# DISPC register map
Vendor: Texas Instruments
Peripheral module from a debugger description file (folder TDA2Px).
Registers are 32-bit, access per field, reset 0x0 unless marked. A register's access mark holds for its fields unless they carry their own. Offsets are as the file gives them; lines under a group give offsets from that group; [hi:lo] are bit positions; {n}, {i} and the like mark numbered series; 'fields as' and 'values as' point back to an identical list; <NAME> marks a mode.

## DISPC (part 1 of 6)
0x00 DISPC_REVISION ro reset not defined — IP Revision
  [31:0] REVISION — IP revision
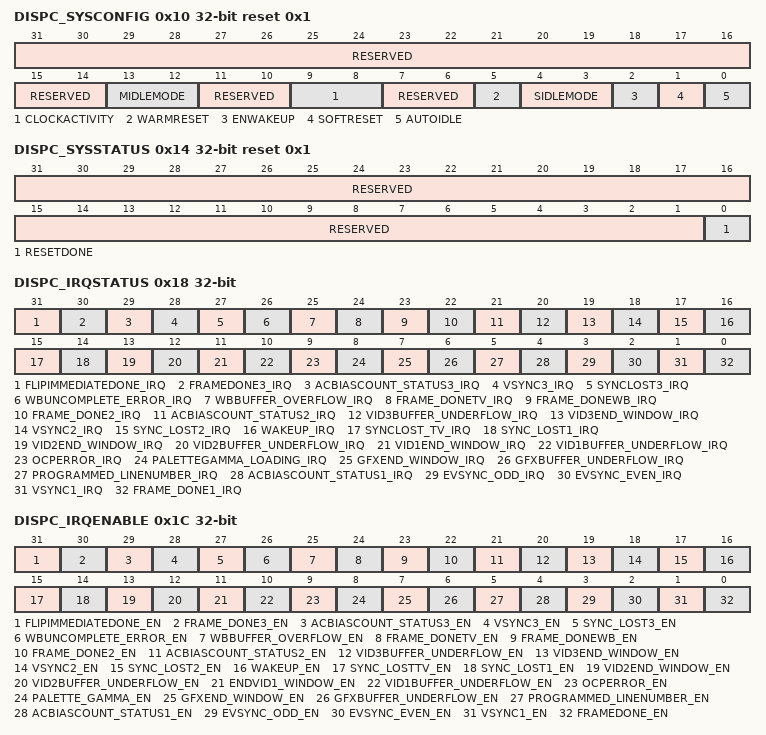
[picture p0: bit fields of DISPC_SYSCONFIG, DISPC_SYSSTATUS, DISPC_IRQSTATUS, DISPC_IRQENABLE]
0x10 DISPC_SYSCONFIG reset 0x1 — This register allows to control various parameters of the OCP interface.
  [31:14] RESERVED ro — Write 0s for future compatibility. Reads returns 0.
  [13:12] MIDLEMODE rw — Master interface power management, standby/wait control
    0=fStandBy (Force-standby. MStandby is only asserted when the module is disabled. MStandby is only asserted when the module is disabled.); 1=nStandBy (No-Standby: MStandby is never asserted.); 2=Sstandby (Smart-Standby. MStandby is asserted based on the internal activity of the module.)
  [11:10] RESERVED ro — Write 0s for future compatibility. Reads returns 0
  [9:8] CLOCKACTIVITY rw — Clocks activity during wake up mode period
    0=OCPFuncOff (OCP and functional clocks can be switched off.); 1=FuncOff (Functional clocks can be switched off and OCP clocks are maintained during wake up period.); 2=OCPOff (OCP clocks can be switched off and Functional clocks are maintained during wake up period.); 3=OCPFuncOn (OCP and functional clocks are maintained during wake-up period.)
  [7:6] RESERVED ro — Write 0s for future compatibility. Reads returns 0
  [5] WARMRESET rw — Warm reset. Set this bit to 1 triggers a module warm reset. The bit is automatically reset by the hardware. During reads, it always returns 0. The warm reset keep the configuration registers unchanged.
    0=Normal mode; 1=warmreset (The warm reset is set.)
  [4:3] SIDLEMODE rw — Slave interface power management, Idle req/ack control
    0=fIdle (Force-idle. An idle request is acknowledged unconditionally.); 1=nIdle (No-idle. An idle request is never acknowledged.); 2=sIdle (Smart-idle. Acknowledgment to an idle request is given based on the internal activity of the module.)
  [2] ENWAKEUP rw — WakeUp feature control
    0=WakeUpDis (Wakeup is disabled.); 1=WakeUpEnb (Wakeup is enabled.)
  [1] SOFTRESET rw — Software reset. Set this bit to 1 to trigger a module reset. The bit is automatically reset by the hardware. During reads, it always returns 0.
    0=nMode (Normal mode); 1=Rst (The module is reset.)
  [0] AUTOIDLE rw — Internal interface clock gating strategy
    0=ClkFree (Interface clock is free-running.); 1=ClkGated (Automatic interface L3_MAIN gating strategy is applied, based on the OCP interface activity. Automatic functional clock gating is also applied to the functional clock based on the module activity (for instance DISPC_<pipe>_ATTRIBUTES.ENABLE).)
0x14 DISPC_SYSSTATUS ro reset 0x1 — This register provides status information about the module, excluding the interrupt status information.
  [31:1] RESERVED — Write 0s for future compatibility. Reads return 0.
  [0] RESETDONE — Internal reset monitoring
    0=rstongoing (Internal module reset is on-going.); 1=rstcomp (Reset completed)
0x18 DISPC_IRQSTATUS access not given — This register regroups all the status of the module internal events that generate an interrupt. Write 1 to a given bit resets this bit
  [31] FLIPIMMEDIATEDONE_IRQ — Flip Immediate Done. The DMA engine has acknowledged the immediate BA change, and software can write the new BA0. (access RW W1toClr)
    0=False (READS: Event is false. WRITES: Status bit unchanged.); 1=True (READS: Event is true (pending). WRITES: Status bit is reset.)
  [30] FRAMEDONE3_IRQ — Frame done for the third LCD. The third LCD output has been disabled by user. All the data have been sent. (access RW W1toClr)
    values as FLIPIMMEDIATEDONE_IRQ
  [29] ACBIASCOUNT_STATUS3_IRQ — AC bias count status for the third LCD (access RW W1toClr)
    values as FLIPIMMEDIATEDONE_IRQ
  [28] VSYNC3_IRQ — Vertical synchronization for the third LCD (access RW W1toClr)
    values as FLIPIMMEDIATEDONE_IRQ
  [27] SYNCLOST3_IRQ — Synchronization lost on the third LCD output. The required data are not output at the correct time due to too short blanking periods or stall of at least one pipelines associated with the third LCD output. (access RW W1toClr)
    values as FLIPIMMEDIATEDONE_IRQ
  [26] WBUNCOMPLETE_ERROR_IRQ — Write-back DMA buffer is flushed before it is completely drained.In WB capture mode, if the new frame starts before the WB DMA buffers are fully drained (onto external memory), then the contents of the WB DMA buffers are lost (implying last few pixels/lines are corrupted in the captured frame in memory). This interrupt is an indication of that case and will trigger every frame . (access RW W1toClr)
    0=READS:_WRITES:_0 (READS: Event is false. WRITES: Status bit unchanged); 1=READS:_WRITES:_1 (READS: Event is true (Pending) WRITES: Status bit is reset)
  [25] WBBUFFER_OVERFLOW_IRQ — Write-back DMA buffer overflow. The DMA buffer is full. (access RW W1toClr)
    0=READS:_WRITES:_0 (READS: Event is false. WRITES: Status bit unchanged.); 1=READS:_WRITES:_1 (READS: Event is true (pending). WRITES: Status bit is reset.)
  [24] FRAME_DONETV_IRQ — Frame done for the TV. The TV output has been disabled by user. All the data have been sent. (access RW W1toClr)
    values as FLIPIMMEDIATEDONE_IRQ
  [23] FRAME_DONEWB_IRQ — Frame done for the write-back channel. The write-back channel has output the frame. All the data of the frame have been sent to the memory. There is no pending data inside the DMA engine for the write-back channel to be transferred to memory. It is available only when the write-back pipeline transfers back to memory the output of one of the pipelines. In case of overlay capture, the interrupt is not generated and the user shall use the FrameDone for the corresponding captured output. (access RW W1toClr)
    values as FLIPIMMEDIATEDONE_IRQ
  [22] FRAME_DONE2_IRQ — Frame done for the secondary LCD. The secondary LCD output has been disabled by user. All the data have been sent. (access RW W1toClr)
    values as FLIPIMMEDIATEDONE_IRQ
  [21] ACBIASCOUNT_STATUS2_IRQ — AC bias count status for the secondary LCD (access RW W1toClr)
    values as FLIPIMMEDIATEDONE_IRQ
  [20] VID3BUFFER_UNDERFLOW_IRQ — Video 3 DMA buffer underflow. The DMA buffer is not necessarily empty but required data are not present in the DMA buffer (due to out of order responses) (access RW W1toClr)
    values as FLIPIMMEDIATEDONE_IRQ
  [19] VID3END_WINDOW_IRQ — The end of the video 3 window has been reached. It is detected by the overlay manager when the full video 3 has been displayed. (access RW W1toClr)
    values as FLIPIMMEDIATEDONE_IRQ
  [18] VSYNC2_IRQ — Vertical synchronization for the secondary LCD (access RW W1toClr)
    values as FLIPIMMEDIATEDONE_IRQ
  [17] SYNC_LOST2_IRQ — Synchronization lost on the secondary LCD output. The required data are not output at the correct time due to too short blanking periods or stall of at least one pipelines associated with the secondary LCD output. (access RW W1toClr)
    values as FLIPIMMEDIATEDONE_IRQ
  [16] WAKEUP_IRQ — Wakeup (access RW W1toClr)
    values as FLIPIMMEDIATEDONE_IRQ
  [15] SYNCLOST_TV_IRQ — Synchronization lost on the TV output. The required data are not output at the correct time due to too short blanking periods or stall of at least one pipelines associated with the TV output. (access RW W1toClr)
    values as FLIPIMMEDIATEDONE_IRQ
  [14] SYNC_LOST1_IRQ — Synchronizationl ost on the primary LCD output. The required data are not output at the correct time due to too short blanking periods or stall of at least one pipelines associated with the primary LCD output. (access RW W1toClr)
    values as FLIPIMMEDIATEDONE_IRQ
  [13] VID2END_WINDOW_IRQ — The end of the video 2 Window has been reached. It is detected by the overlay manager when the full video 2 has been displayed. (access RW W1toClr)
    values as FLIPIMMEDIATEDONE_IRQ
  [12] VID2BUFFER_UNDERFLOW_IRQ — Video 2 DMA buffer underflow. The DMA buffer is not necessarily empty but required data are not present in the DMA buffer (due to out of order responses) (access RW W1toClr)
    values as FLIPIMMEDIATEDONE_IRQ
  [11] VID1END_WINDOW_IRQ — The end of the video 1 Window has been reached. It is detected by the overlay manager when the full video 1 has been displayed. (access RW W1toClr)
    values as FLIPIMMEDIATEDONE_IRQ
  [10] VID1BUFFER_UNDERFLOW_IRQ — Video 1 DMA buffer underflow. The DMA buffer is not necessarily empty but required data are not present in the DMA buffer (due to out of order responses) (access RW W1toClr)
    values as FLIPIMMEDIATEDONE_IRQ
  [9] OCPERROR_IRQ — OCP error. L3_MAIN Interconnect has sent SResp=ERR. (access RW W1toClr)
    values as FLIPIMMEDIATEDONE_IRQ
  [8] PALETTEGAMMA_LOADING_IRQ — Palette Gamma loading status. The palette used as Color Look Up Table (CLUT) for the graphics BITMAP formats (1-, 2-, 4-, or 4-bpp) or as gamma table for the overlay output for the primary LCD output has been loaded successfully.NOTE: CLUT and BITMAP formats are not supported in this family of devices. . (access RW W1toClr)
    values as FLIPIMMEDIATEDONE_IRQ
  [7] GFXEND_WINDOW_IRQ — The end of the graphics wndow has been reached. It is detected by the overlay manager when the full graphics has been displayed. (access RW W1toClr)
    values as FLIPIMMEDIATEDONE_IRQ
  [6] GFXBUFFER_UNDERFLOW_IRQ — Graphics DMA buffer underflow. The DMA buffer is not necessarily empty but required data are not present in the DMA buffer (due to out of order responses) (access RW W1toClr)
    values as FLIPIMMEDIATEDONE_IRQ
  [5] PROGRAMMED_LINENUMBER_IRQ — Programmed line number. It indicates that the scan of the primary LCD has reached the programmed user line number. (access RW W1toClr)
    values as FLIPIMMEDIATEDONE_IRQ
  [4] ACBIASCOUNT_STATUS1_IRQ — AC bias count status for the primary LCD (access RW W1toClr)
    values as FLIPIMMEDIATEDONE_IRQ
  [3] EVSYNC_ODD_IRQ — VSYNC for odd field from the TV encoder (HDMI) (access RW W1toClr)
    values as FLIPIMMEDIATEDONE_IRQ
  [2] EVSYNC_EVEN_IRQ — VSYNC for even field from the TV encoder (HDMI) (access RW W1toClr)
    values as FLIPIMMEDIATEDONE_IRQ
  [1] VSYNC1_IRQ — Vertical synchronization for the primary LCD. (access RW W1toClr)
    values as FLIPIMMEDIATEDONE_IRQ
  [0] FRAME_DONE1_IRQ — Frame done for the primary LCD. The primary LCD output has been disabled by user. All the data have been sent. (access RW W1toClr)
    values as FLIPIMMEDIATEDONE_IRQ
0x1C DISPC_IRQENABLE rw — This register allows to mask/unmask the module internal sources of interrupt, on an event-by-event basis
  [31] FLIPIMMEDIATEDONE_EN — Flip Immediate Done. The DMA engine has acknowledged the immediate BA change, and software can write the new BA0.
    0=masked (FrameDone for the primary LCD output is masked); 1=genint (FrameDone for the primary LCD output generates an interrupt when it occurs)
  [30] FRAME_DONE3_EN — Frame done for the third LCD. The third LCD output has been disabled by user. All the data have been sent.
    0=masked (Frame Done for the secondary LCD is masked.); 1=genint (Frame Done for the secondary LCD generates an interrupt when it occurs.)
  [29] ACBIASCOUNT_STATUS3_EN — AC Bias count status for the third LCD
    0=masked (ACBiasCountStatus for the secondary LCD output is masked); 1=genint (ACBiasCountStatus for the secondary LCD output generates an interrupt when it occurs)
  [28] VSYNC3_EN — Vertical synchronization for the third LCD
    0=masked (VSYNC for the secondary LCD output is masked.); 1=genint (VSYNC for the secondary LCD output generates an interrupt when it occurs.)
  [27] SYNC_LOST3_EN — Synchronization lost on the third LCD output. The required data are not output at the correct time due to too short blanking periods or stall of at least one pipelines associated with the third LCD output.
    0=masked (Synchronization Lost on the secondary LCD output is masked.); 1=genint (Synchronization Lost on the secondary LCD output generates an interrupt when it occurs.)
  [26] WBUNCOMPLETE_ERROR_EN — The write back buffer has been flushed before been fully drained. Enable.
    0=masked (Interrupt is masked.); 1=genint (Interrupt is enabled.)
  [25] WBBUFFER_OVERFLOW_EN — Write-back DMA buffer overflow. The DMA buffer is full.
    0=masked (WBBufferOverflow is masked.); 1=genint (WBBufferOverflow generates an interrupt when it occurs.)
  [24] FRAME_DONETV_EN — Frame done for the TV. The TV output has been disabled by user. All the data have been sent.
    0=masked (Frame Done for the TV output is masked.); 1=genint (Frame Done for the TV output generates an interrupt when it occurs.)
  [23] FRAME_DONEWB_EN — Frame done for the write-back channel. The write-back channel has output the frame. All the data have been sent for the frame have been sent to the memory. There is no pending data inside the DMA engine for the write-back channel to be transferred to memory.
    0=masked (Frame done for the write-back is masked.); 1=genint (Frame done for the write-back generates an interrupt when it occurs.)
  [22] FRAME_DONE2_EN — Frame done for the secondary LCD. The secondary LCD output has been disabled by user. All the data have been sent.
    0=masked (Frame done for the secondary LCD is masked.); 1=genint (Frame done for the secondary LCD generates an interrupt when it occurs.)
  [21] ACBIASCOUNT_STATUS2_EN — AC Bias count status for the secondary LCD
    0=masked (ACBiasCountStatus for the secondary LCD output is masked.); 1=genint (ACBiasCountStatus for the secondary LCD output generates an interrupt when it occurs.)
  [20] VID3BUFFER_UNDERFLOW_EN — Video 3 DMA Buffer Underflow. The DMA buffer is not necessary empty but required data are not present in the DMA buffer (due to out of order responses)
    0=masked (Vid3BufferUnderflow is masked.); 1=genint (Vid3BufferUnderflow generates an interrupt when it occurs.)
  [19] VID3END_WINDOW_EN — The end of the video 3 window has been reached. It is detected by the overlay manager when the full video 3 has been displayed.
    0=masked (Vid3EndWindow is masked.); 1=genint (Vid3EndWindow generates an interrupt when it occurs.)
  [18] VSYNC2_EN — Vertical synchronization for the secondary LCD
    values as VSYNC3_EN
  [17] SYNC_LOST2_EN — Synchronization lost on the secondary LCD output. The required data are not output at the correct time due to too short blanking periods or stall of at least one pipelines associated with the secondary LCD output.
    values as SYNC_LOST3_EN
  [16] WAKEUP_EN — Wake up mask
    0=masked (WakeUp is masked.); 1=genint (WakeUp generates an interrupt when it occurs.)
  [15] SYNC_LOSTTV_EN — Synchronization lost on the TV output. The required data are not output at the correct time due to too short blanking periods or stall of at least one pipelines associated with the TV output.
    0=masked (Synchronization Lost on the TV output is masked.); 1=genint (Synchronization Lost on the TV output generates an interrupt when it occurs.)
  [14] SYNC_LOST1_EN — Synchronization lost for the primary LCD
    0=masked (SyncLost for the primary LCD output is masked.); 1=genint (SyncLost for the primary LCD output generates an interrupt when it occurs.)
  [13] VID2END_WINDOW_EN — The end of the video 2 Window has been reached. It is detected by the overlay manager when the full video 2 has been displayed.
    0=masked (Vid2EndWindow is masked.); 1=genint (Vid2EndWindow generates an interrupt when it occurs.)
  [12] VID2BUFFER_UNDERFLOW_EN — Video 2 DMA buffer underflow. The DMA buffer is not necessary empty but required data are not present in the DMA buffer (due to out of order responses)
    0=masked (Vid2BufferUnderflow is masked.); 1=genint (Vid2BufferUnderflow generates an interrupt when it occurs.)
  [11] ENDVID1_WINDOW_EN — The end of the video 1 window has been reached. It is detected by the overlay manager when the full video 1 has been displayed.
    0=masked (EndVid1Window is masked.); 1=genint (EndVid1Window generates an interrupt when it occurs.)
  [10] VID1BUFFER_UNDERFLOW_EN — Video 1 DMA buffer underflow. The DMA buffer is not necessary empty but required data are not present in the DMA buffer (due to out of order responses)
    0=masked (Vid1bufferunderflow is masked.); 1=genint (Vid1bufferunderflow generates an interrupt when it occurs.)
  [9] OCPERROR_EN — OCP Error. L3_MAIN Interconnect has sent SResp=ERR.
    0=masked (OCPError is masked.); 1=genint (OCPError generates an interrupt when it occurs.)
  [8] PALETTE_GAMMA_EN — Palette gamma loading mask. The palette used as Color Look Up Table (CLUT) for the graphics BITMAP formats (1-, 2-, 4-, or 4-bpp) or as gamma table for the overlay output for the primary LCD output has been loaded successfully.NOTE: CLUT and BITMAP formats are not supported in this family of devices. .
    0=masked (PaletteGamma is masked.); 1=genint (PaletteGamma generates an interrupt when it occurs.)
  [7] GFXEND_WINDOW_EN — The end of the graphics Window has been reached. It is detected by the overlay manager when the full graphics has been displayed.
    0=masked (GfxEndWindow is masked.); 1=genint (GfxEndWindow generates an interrupt when it occurs.)
  [6] GFXBUFFER_UNDERFLOW_EN — Graphics DMA Buffer Underflow. The DMA buffer is not necessarily empty but required data are not present in the DMA buffer (due to out of order responses)
    0=masked (GfxBufferUnderflow is masked.); 1=genint (GfxBufferUnderflow generates an interrupt when it occurs.)
  [5] PROGRAMMED_LINENUMBER_EN — Programmed Line Number. It indicates that the scan of the primary LCD has reached the programmed user line number.
    0=masked (ProgrammedLineNumber is masked.); 1=genint (ProgrammedLineNumber generates an interrupt when it occurs.)
  [4] ACBIASCOUNT_STATUS1_EN — AC Bias count status for the primary LCD
    0=masked (ACBiascountstatus for the primary LCD output is masked.); 1=genint (ACBiascountstatus for the primary LCD output generates an interrupt when it occurs.)
  [3] EVSYNC_ODD_EN — VSYNC for odd field from the TV encoder (HDMI)
    0=masked (EVSYNC_ODD for the TV output is masked.); 1=genint (EVSYNC_ODD for the TV output generates an interrupt when it occurs.)
  [2] EVSYNC_EVEN_EN — VSYNC for even field from the TV encoder (HDMI)
    0=masked (EVSYNC_EVEN for the TV output is masked.); 1=genint (EVSYNC_EVEN for the TV output generates an interrupt when it occurs.)
  [1] VSYNC1_EN — Vertical synchronization for the primary LCD.
    0=masked (VSYNC for the primary LCD output is masked.); 1=genint (VSYNC for the primary LCD output generates an interrupt when it occurs.)
  [0] FRAMEDONE_EN — Frame done for the primary LCD. The primary LCD output has been disabled by user. All the data have been sent.
    0=masked (Frame Done for the primary LCD output is masked.); 1=genint (FrameDone for the primary LCD output generates an interrupt when it occurs.)
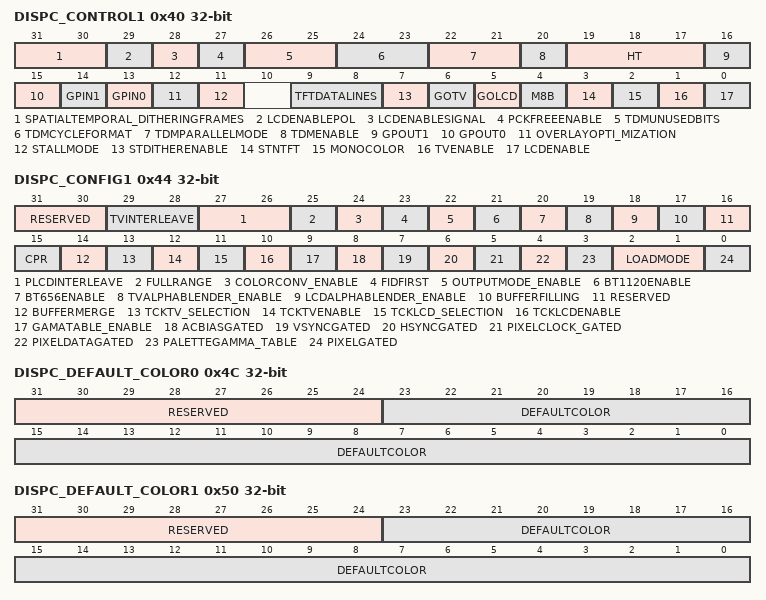
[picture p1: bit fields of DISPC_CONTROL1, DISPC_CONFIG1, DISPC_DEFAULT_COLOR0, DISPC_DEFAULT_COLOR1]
0x40 DISPC_CONTROL1 — The control register configures the Display Controller module for the primary LCD and TV outputs.
  [31:30] SPATIALTEMPORAL_DITHERINGFRAMES rw — Spatial/temporal dithering number of frames for the primary LCD output wr: VFP start period of primary LCD
    0=OneFrame (Spatial only); 1=TwoFrames (Spatial and temporal over 2 frames); 2=FourFrames (Spatial and temporal over 4 frames)
  [29] LCDENABLEPOL ro — Write 0s for future compatibility. Reads return 0.
  [28] LCDENABLESIGNAL ro — Write 0s for future compatibility. Reads return 0.
  [27] PCKFREEENABLE ro — Write 0s for future compatibility. Reads return 0.
  [26:25] TDMUNUSEDBITS rw — State of unused bits (TDM mode only) for the primary LCD output. wr: VFP start period of primary LCD
    0=Low level (0); 1=High level (1); 2=Unchanged from previous state
  [24:23] TDMCYCLEFORMAT rw — Cycle format (TDM mode only) for the primary LCD output WR: VFP start period of primary LCD
    0=1CycPerPix (1 cycle for 1 pixel); 1=2CycPerPix (2 cycles for 1 pixel); 2=3CycPerPix (3 cycles for 1 pixel); 3=3CycPer2Pix (3 cycles for 2 pixels)
  [22:21] TDMPARALLELMODE rw — Output interface width (TDM mode only) for the primary LCD output WR: VFP start period of primary LCD
    0=8bParaInt (8-bit parallel output interface selected); 1=9bParaInt (9-bit parallel output interface selected); 2=12bParaInt (12-bit parallel output interface selected); 3=16bParaInt (16-bit parallel output interface selected)
  [20] TDMENABLE rw — Enable the multiple cycle format for the primary LCD output. WR: VFP start period of primary LCD
    0=TDM disabled; 1=TDMEnb (TDM enabled)
  [19:17] HT rw — Hold time for TV output WR: EVSYNC Encoded value (from 1 to 8) to specify the number of external digital clock periods to hold the data (programmed value = value minus 1)
  [16] GPOUT1 rw — General purpose output signal l WR: immediate
    0=reset (The GPout1 is reset.); 1=set (The GPout1 is set.)
  [15] GPOUT0 rw — General Purpose Output Signal WR:immediate
    0=reset (The GPout0 is reset.); 1=set (The GPout0 is set.)
  [14] GPIN1 ro — General purpose input signal WR: immediately
    0=reset (The GPin1 has been reset.); 1=set (The GPin1 has been set.)
  [13] GPIN0 ro — General purpose input signal WR: immediately
    0=GPin0Rst (The GPin0 has been reset.); 1=GPin0Set (The GPin0 has been set.)
  [12] OVERLAYOPTI_MIZATION rw — Overlay optimization for the primary LCD output WR: VFP start period of the primary LCD
    0=GDBVWfM (All the data for all the enabled pipelines are fetched from memory regardless of the overlay/alpha blending configuration.); 1=GDBVWnfM (The data not used by the overlay manager because of overlap between layers with no alpha blending between them must not be fetched from memory in order to optimize the bandwidth.)
  [11] STALLMODE rw — STALL mode for the primary LCD output wr: VFP start period of primary LCD
    0=Normal_mode_selected; 1=STALL_VSYNC/HSYNC._LCD_LCD_1 (STALL mode selected. The Display Controller sends the data without considering the VSYNC/HSYNC. The LCD output is disabled at the end of the transfer of the frame. To generate a new frame, the software must re-enable the LCD output.)
  [9:8] TFTDATALINES rw — Number of lines of the primary LCD interface WR: VFP start period of primary LCD
    0=OaLSB12b (12-bit output aligned on the LSB of the pixel data interface); 1=OaLSB16b (16-bit output aligned on the LSB of the pixel data interface); 2=OaLSB18b (18-bit output aligned on the LSB of the pixel data interface); 3=OaLSB24b (24-bit output aligned on the LSB of the pixel data interface)
  [7] STDITHERENABLE rw — Spatial temporal dithering enable for the primary LCD output WR: VFP start period of primary LCD
    0=STDithDis (Spatial/temporal dithering logic disabled); 1=STDithEnb (Spatial/temporal dithering logic enabled)
  [6] GOTV rw — GO command for the TV output. It is used to synchronized the pipelines (graphics and/or video ones) associated with the TV output. WR: immediate
    0=HfUISR (The hardware has finished updating the internal shadow registers of the pipeline(s) associated with the TV output using the user values. The hardware resets the bit when the update is completed.); 1=UfPSR (The user has finished to program the shadow registers of the pipeline(s) associated with the TV output and the hardware can update the internal registers at the external VSYNC.)
  [5] GOLCD rw — GO command for the primary LCD output. It is used to synchronized the pipelines (graphics and/or video ones) associated with the primary LCD output. WR: immediate
    0=HfUISR (The hardware has finished updating the internal shadow registers of the pipeline(s) connected to the LCD output using the user values. The hardware resets the bit when the update is completed.); 1=UfPSR (The user has finished to program the shadow registers of the pipeline(s) associated with the LCD output and the hardware can update the internal registers at the VFP start period)
  [4] M8B rw — Mono 8-bit mode of the primary LCD wr: VFP start period of primary LCD output
    0=4PixtoPanel (Reserved); 1=8PixtoPanel (Reserved)
  [3] STNTFT rw — LCD Display type of the primary LCD WR: VFP start period of primary LCD output
    0=STNdispEnb (STN display operation enabled. STN dither logic is enabled.); 1=ATFTDisEnb (Active or TFT display operation enabled. STN Dither logic and output FIFO bypassed.)
  [2] MONOCOLOR rw — Monochrome/color selection for the primary LCD WR: VFP start period of primary LCD output
    0=ColOpEnb (Color operation enabled (STN mode only)); 1=MonOpEnb (Monochrome operation enabled (STN mode only))
  [1] TVENABLE rw — Enable the TV output wr: immediate effect only occurs at the end of the current frame.
    0=DigOpDis (TV output disabled (at the end of the current field if interlace output when the bit is reset)); 1=DigOpEnb (TV output enabled)
  [0] LCDENABLE rw — Enable the primary LCD outputs wr: immediate Effect only occurs at the end of the current frame
    0=LCDOpDis (LCD output disabled (at the end of the frame when the bit is reset)); 1=LCDOpEnb (LCD output enabled)
0x44 DISPC_CONFIG1 — The control register configures the Display Controller module for the primary LCD output and TV output. Shadow register, updated on VFP start period of primary LCD or EVSYNC or when.GOWB is set to 1 by software and current WB frame is finished (no more data in the write-back pipeline). The synchronization event is defined based on the output using the pipeline: primary LCD, secondary LCD, third LCD, TV output or write-back to the memory
  [31:30] RESERVED ro — Write 0s for future compatibility. Reads return 0.
  [29:28] TVINTERLEAVE rw — TV Interleave Pattern
  [27:26] PLCDINTERLEAVE rw — pLCD Interleave Pattern
  [25] FULLRANGE rw — Color Space Conversion full range setting. wr: VFP start of primary LCD
    0=Limrange (Limited range selected.); 1=Full range selected
  [24] COLORCONV_ENABLE rw — Enable the color space conversion. It shall be reset when CPR bit field is set to 0x1. wr: VFP start of primary LCD
    0=ColSpCDis (Disable Color Space Conversion RGB to YUV); 1=ColSpCEnb (Enable Color Space Conversion RGB to YUV)
  [23] FIDFIRST rw — Selects the first field to output in case of interlace mode. In case of progressive mode, the value is not used. wr: VFP start of primary LCD
    0=Even (First field is even.); 1=Odd (Odd field is first.)
  [22] OUTPUTMODE_ENABLE rw — Selects between progressive and interlace mode for the primary LCD output. wr: VFP start of primary LCD
    0=Disable (Progressive mode selected.); 1=Enable (Interlace mode selected.)
  [21] BT1120ENABLE rw — Selects BT.1120 format on the primary LCD output. It is not posssible to enable BT.656 and BT.1120 at the same time one the same LCD output. wr: VFP start of primary LCD
    0=BT.1120_is_disabled; 1=BT.1120_is_enabled
  [20] BT656ENABLE rw — Selects BT.656 format on the primary LCD output. It is not posssible to enable BT.656 and BT.1120 at the same time one the same LCD output. wr: VFP start of primary LCD
    0=BT.656_is_disabled; 1=BT.656_is_enabled
  [19] TVALPHABLENDER_ENABLE rw — Selects the alpha blender overlay manager for the TV output instead of the color key alpha blender (LCD output). The bit field is deprecated. It is present for software backward compatibility only. When it is enabled, the Z-order defined in each ATTRIBUTES registers for only the pipelines associated pipeline connected to the TV output are invalid and replaced by the following: graphics z-order = 3, video3 z-order = 2, video2 z-order =1 and video1 z-order=0 If it disabled, the z-order and z-order enable bit fields defined in each ATTRIBUTES register are used. wr: EVSYNC start of primary LCD
    0=Disable (Alpha blender is disabled.); 1=Enable (The alpha blender is enabled.)
  [18] LCDALPHABLENDER_ENABLE rw — Selects the alpha blender overlay manager for the primary LCD output instead of the color key alpha blender (LCD output). The bit field is deprecated. It is present for software backward compatibility only. When it is enabled, the Z-order defined in each ATTRIBUTES registers for only the pipelines associated with the primary LCD output are invalid and replaced by the following: graphics z-order = 3, video3 z-order = 2, video2 z-order =1 and video1 z-order=0 If it disabled, the z-order and z-order enable bit fields defined in each ATTRIBUTES register are used. wr: VFP start of primary LCD
    0=Disable (Alpha blender is disabled. The color key alpha blending is used.); 1=Enable (The alpha blender is enabled.)
  [17] BUFFERFILLING rw — Controls if the DMA buffers are refilled only when the LOW threshold is reached or if all DMA buffers are refilled when at least one of them reaches the LOW threshold. wr: immediate
    0=FIFOfillingDis (Each DMA buffer is refilled when it reaches LOW threshold.); 1=FIFOfillingEnb (All DMA buffers are refilled up to high threshold when at least one of them reaches the LOW threshold. (only active DMA buffers shall be considered and when reaching the end of the frame the DMA buffer goes to empty condition so no need to fill it again).)
  [16] RESERVED rw — Write 0s for future compatibility. Reads return 0.
  [15] CPR rw — Color phase rotation control (primary LCD output). It shall be reset when ColorConvEnable bit field is set to 1 wr: VFP start period of primary LCD output
    0=CPRDis (Color Phase Rotation Disabled); 1=CPREnb (Color Phase Rotation Enabled)
  [14] BUFFERMERGE rw — Buffer merge control wr: EVSYNC or whenDISPC_CONTROL2.GOWB is set to 1 by software and current WB frame is finished (no more data in the write-back pipeline). The synchronization event is defined based on the output using the pipeline: primary LCD, secondary LCD, third LCD, TV output or write-back to the memory or VFP When enabled, the DISPC_GLOBAL_BUFFER register is ignored. This bit must be set to zero when the write back channel is used. When DISPC_CONTROL2.GOWB is used BUFFERMERGE MUST be zero. When DISPC_CONTROL2.GOWB is used BUFFERMERGE MUST be zero. WR: immediate
    0=MergeDis (DMA buffer merge disabled Each DMA buffer is dedicated to one pipeline.); 1=MergeEnb (DMA buffer merge enabled All the DMA buffers are merged into a single one to be used by the single active pipeline.)
  [13] TCKTV_SELECTION rw — Transparency color key selection (TV output) wr: EVSYNC
    0=GDTCK (Destination transparency color key selected); 1=VSTCK (Source transparency color key selected)
  [12] TCKTVENABLE rw — Transparency color key enabled (TV output) WR: EVSYNC
    0=DisTCK (Disable the transparency color key for the TV output); 1=EnbTCK (Enable the transparency color key for the TV output)
  [11] TCKLCD_SELECTION rw — Transparency color key selection (primary LCD output) wr: VFP start period of primary LCD output
    0=GDTK (Destination transparency color key selected); 1=VSTK (Source transparency color key selected)
  [10] TCKLCDENABLE rw — Transparency color key enabled (primary LCD output) wr: VFP start period of primary LCD output
    0=DisTCK (Disable the transparency color key for the LCD); 1=EnbTCK (Enable the transparency color key for the LCD)
  [9] GAMATABLE_ENABLE rw — For backward compatibility, an enable bit has been added on the 2 additional gamma tables (secondary display and TV). Gamma table of LCD1 is always enabled.
    0=GammaTableEn (Gamma table LCD2 and TV are bypassed); 1=GammaTableDis (Gamma table LCD2 and TV are enabled)
  [8] ACBIASGATED rw — ACBias Gated Enabled (primary LCD output) wr: VFP start period of primary LCD output
    0=ACBGDis (AcBias gated disabled); 1=ACBGEnb (AcBias gated enabled)
  [7] VSYNCGATED rw — VSYNC Gated Enabled (primary LCD output) wr: VFP start period of primary LCD output
    0=VGDis (VSYNC gated disabled); 1=VGEnb (VSYNC gated enabled)
  [6] HSYNCGATED rw — HSYNC Gated Enabled (primary LCD output) wr: VFP start period of primary LCD output
    0=HGDis (HSYNC gated disabled); 1=HGEnb (HSYNC gated enabled)
  [5] PIXELCLOCK_GATED rw — Pixel Clock Gated Enabled (primary LCD output) wr: VFP start period of primary LCD output
    0=PCGDis (Pixel clock gated disabled); 1=PCGEnb (Pixel clock gated enabled)
  [4] PIXELDATAGATED rw — Pixel data gated enabled (primary LCD output) wr: VFP start period of primary LCD output
    0=PDGDis (Pixel data gated disabled); 1=PDGEnb (Pixel data gated enabled)
  [3] PALETTEGAMMA_TABLE rw — Palette/gamma table selection wr: VFP start period of primary LCD output or VFP start period of secondary LCD output or EVSYNC or whenDISPC_CONTROL2.GOWB is set to 1 by software and current WB frame is finished (no more data in the write-back pipeline). The synchronization event is defined based on the output using the graphics pipeline: primary LCD, secondary LCD, third LCD, TV output or write-back to the memory. In case of the table is used as gamma table, it is used for the primary LCD output only.NOTE: CLUT and BITMAP formats are not supported in this family of devices. .
    0=LUTPallette (LUT used as palette (only if graphics format is BITMAP1, 2, 4, and 8)); 1=LUTgTable (LUT used as gamma table (only if graphics format is NOT BITMAP1, 2, 4, and 8 or no graphics window present))
  [2:1] LOADMODE rw — Loading mode for the palette/gamma table wr: VFP start period of primary LCD output or VFP start period of secondary LCD output or EVSYNC or whenDISPC_CONTROL2.GOWB is set to 1 by software and current WB frame is finished (no more data in the write-back pipeline). The synchronization event is defined based on the output using the pipeline: primary LCD, secondary LCD, third LCD, TV output or write-back to the memory
    0=PgTabLeFr (Palette/Gamma Table and data are loaded every frame); 1=FrDatLeFr (Palette/Gamma Table to be loaded. The user sets the bit when the palette/gamma table has to be loaded. Hardware resets the bit to 0x2 when table has been loaded. (.ENABLE has to be set to 1).); 2=FrDatLeFr (Frame data only loaded every frame); 3=DLoFrSw (Palette/Gamma Table and frame data loaded on first frame then switch to 0x2 (Hardware).)
  [0] PIXELGATED rw — Pixel gated enable (only for TFT) (primary LCD output) wr: VFP start period of primary LCD output
    0=PclkTogA (Pixel clock always toggles (only in TFT mode)); 1=PclkTogV (Pixel clock only toggles when there is valid data to display. (only in TFT mode))
0x4C DISPC_DEFAULT_COLOR0 — The control register allows to configure the default solid background color for the primary LCD. Shadow register, updated on VFP start period of the primary LCD
  [31:24] RESERVED ro — Write 0s for future compatibility. Reads return 0.
  [23:0] DEFAULTCOLOR rw — 24-bit RGB color value to specify the default solid color to display when there is no data from the overlays.
0x50 DISPC_DEFAULT_COLOR1 — The control register allows to configure the default solid background color for the TV output. Shadow register, updated on EVSYNC
  fields as DISPC_DEFAULT_COLOR0
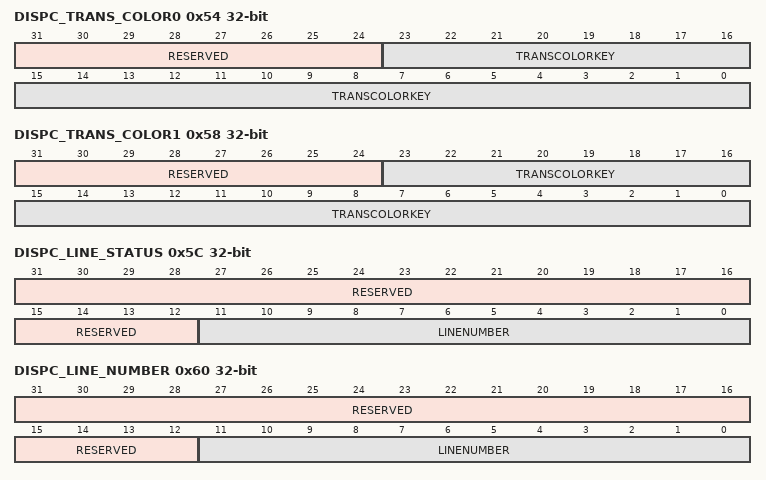
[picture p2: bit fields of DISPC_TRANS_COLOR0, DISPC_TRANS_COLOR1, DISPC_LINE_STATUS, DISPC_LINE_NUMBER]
0x54 DISPC_TRANS_COLOR0 — The register sets the transparency color value for the video/graphics overlays for the primary LCD output. Shadow register, updated on VFP start period of the primary LCD
  [31:24] RESERVED ro — Write 0s for future compatibility. Reads return 0.
  [23:0] TRANSCOLORKEY rw — Transparency color key value in RGB format [0] BITMAP 1 (CLUT), [23,1] set to 0s [1:0] BITMAP 2 (CLUT), [23,2] set to 0s [3:0] BITMAP 4 (CLUT), [23,4] set to 0s [7:0] BITMAP 8 (CLUT), [23,8] set to 0s [11:0] RGB 12, [23,12] set to 0s [15:0] RGB 16, [23,16] set to 0s [23:0] RGB 24NOTE: CLUT and BITMAP formats are not supported in this family of devices. .
0x58 DISPC_TRANS_COLOR1 — The register sets the transparency color value for the video/graphics overlays for the TV output. Shadow register, updated on EVSYNC
  fields as DISPC_TRANS_COLOR0
0x5C DISPC_LINE_STATUS ro — The control register indicates the current primary LCD panel display line number.
  [31:12] RESERVED — Write 0s for future compatibility. Reads return 0.
  [11:0] LINENUMBER — Current LCD panel line number Current display line number. The first active line has the value 0. During blanking lines the line number is not incremented.
0x60 DISPC_LINE_NUMBER — The control register indicates the primary LCD panel display line number for the interrupt and the DMA request. Shadow register, updated on VFP start period of primary LCD.
  [31:12] RESERVED ro — Write 0s for future compatibility. Reads return 0.
  [11:0] LINENUMBER rw — LCD panel line number programming LCD line number defines the line on which the programmable interrupt is generated and the DMA request occurs.
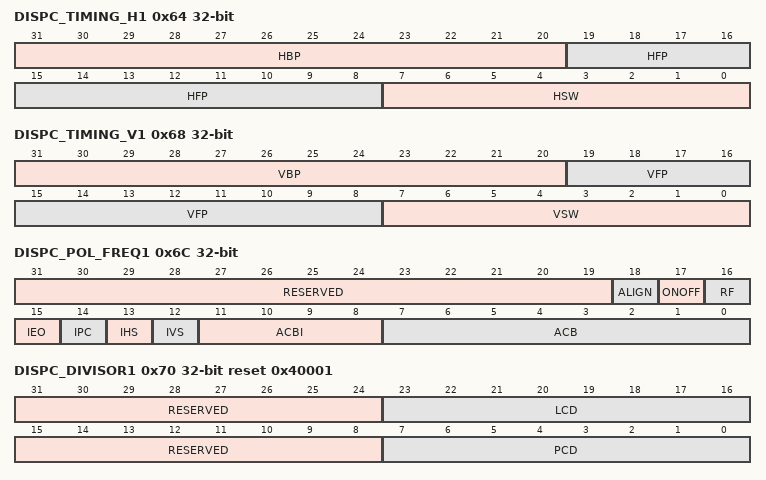
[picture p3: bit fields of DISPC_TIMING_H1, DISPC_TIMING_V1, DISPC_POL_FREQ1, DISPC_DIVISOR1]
0x64 DISPC_TIMING_H1 rw — The register configures the timing logic for the HSYNC signal. It is used for the primary LCD output. Shadow register, updated on VFP start period of primary LCD
  [31:20] HBP — Horizontal Back Porch. Encoded value (from 1 to 4096) to specify the number of pixel clock periods to add to the beginning of a line transmission before the first set of pixels is output to the display (program to value minus 1). When in BT mode and interlaced, this field corresponds to the vertical field blanking No 2 for Even Field.
  [19:8] HFP — Horizontal front porch. Encoded value (from 1 to 4096) to specify the number of pixel clock periods to add to the end of a line transmission before line clock is asserted (program to value minus 1). When in BT mode and interlaced, this field corresponds to the vertical field blanking No 1 for Even Field.
  [7:0] HSW — Horizontal synchronization pulse width. Encoded value (from 1 to 256) to specify the number of pixel clock periods to pulse the line clock at the end of each line (program to value minus 1). When in BT mode, this field corresponds to the horizontal blanking
0x68 DISPC_TIMING_V1 rw — The register configures the timing logic for the VSYNC signal. It is used for the primary LCD output. Shadow register, updated on VFP start period of primary LCD
  [31:20] VBP — Vertical back porch. Encoded value (from 0 to 4095) to specify the number of line clock periods to add to the beginning of a frame.
  [19:8] VFP — Vertical front porch. Encoded value (from 0 to 4095) to specify the number of line clock periods to add to the end of each frame.
  [7:0] VSW — Vertical synchronization pulse width. In active mode, encoded value (from 1 to 256) to specify the number of line clock periods (program to value minus 1) to pulse the frame clock (VSYNC) pin at the end of each frame after the end of frame wait (VFP) period elapses. Frame clock uses as VSYNC signal in active mode.
0x6C DISPC_POL_FREQ1 — The register configures the signal configuration. It is used for the primary LCD output. Shadow register, updated on VFP start period of primary LCD.
  [31:19] RESERVED ro — Write 0s for future compatibility. Reads return 0.
  [18] ALIGN rw — Defines the alignment between HSYNC and VSYNC assertion.
    0=notAligned (VSYNC and HSYNC are not aligned); 1=Aligned (VSYNC and HSYNC assertions are aligned.)
  [17] ONOFF rw — HSYNC/VSYNC Pixel clock Control On/OffNote: Control module register CTRL_CORE_SMA_SW_1[22]DSS_CH0_ON_OFF must be set to match enum=DBit16 .
    0=DOpEdPCk (HSYNC and VSYNC are driven on opposite edges of pixel clock than pixel data); 1=DBit16 (HSYNC and VSYNC are driven according to bit 16)
  [16] RF rw — Program HSYNC/VSYNC Rise or FallNote: Control module register CTRL_CORE_SMA_SW_1[16]DSS_CH0_RF must be set to match enum=DRiEdPCk .
    0=DFEdPCk (HSYNC and VSYNC are driven on falling edge of pixel clock (if bit 17 set to 1)); 1=DRiEdPCk (HSYNC and VSYNC are driven on rising edge of pixel clock (if bit 17 set to 1))
  [15] IEO rw — Invert output enable
    0=ACBaHigh (Ac-bias is active high (active display mode)); 1=ACBaLow (Ac-bias is active low (active display mode))
  [14] IPC rw — Invert pixel clockNote: Control module register CTRL_CORE_SMA_SW_1[19]DSS_CH0_IPC must be set to match enum=DfPCk .
    0=DrPCk (Data is driven on the LCD data lines on the rising-edge of the pixel clock); 1=DfPCk (Data is driven on the LCD data lines on the falling-edge of the pixel clock)
  [13] IHS rw — Invert HSYNC
    0=LCkpinAh (Line clock pin is active high and inactive low); 1=LCkpinAl (Line clock pin is active low and inactive high)
  [12] IVS rw — Invert VSYNC
    0=FCkpinAh (Frame clock pin is active high and inactive low); 1=FCkpinAl (Frame clock pin is active low and inactive high)
  [11:8] ACBI rw — AC Bias pin transitions per interrupt Value (from 0 to 15) used to specify the number of AC Bias pin transitions
  [7:0] ACB rw — AC Bias pin frequency value (from 0 to 255) used to specify the number of line clocks to count before transitioning the AC Bias pin. This pin is used to periodically invert the polarity of the power supply to prevent DC charge build-up within the display.
0x70 DISPC_DIVISOR1 reset 0x40001 — The register configures the divisors. It is used for the primary LCD output Shadow register, updated on VFP start period of primary LCD
  [31:24] RESERVED ro — Write 0s for future compatibility. Reads return 0.
  [23:16] LCD rw — Display controller logic clock divisor value (from 1 to 255) to specify the intermediate pixel clock frequency based on the LCD1_CLK. The value 0 is invalid.
  [15:8] RESERVED ro — Write 0s for future compatibility. Reads return 0.
  [7:0] PCD rw — Pixel clock divisor value (from 1 to 255) to specify the frequency of the pixel clock based on the LCD1_CLK divided byDISPC_DIVISOR1.LCD value. The values 0 is invalid.
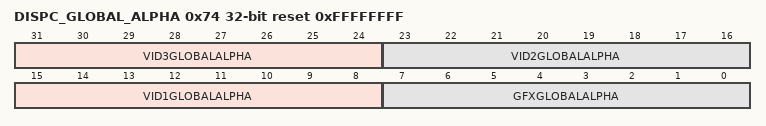
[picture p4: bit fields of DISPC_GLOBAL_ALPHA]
0x74 DISPC_GLOBAL_ALPHA rw reset 0xFFFFFFFF — The register defines the global alpha value for the graphics and three video pipelines. Shadow register, updated on VFP start period of primary LCD or VFP start period of the third LCD or VFP start period of the secondary LCD or VFP start period of the third LCD or EVSYNC or when.GOWB is set to 1 by software and current WB frame is finished (no more data in the write-back pipeline). The synchronization event is defined based on the output using the pipeline: primary LCD, secondary LCD, third LCD, TV output or write-back to the memory for each bit field depending on the association of the each pipeline with the primary LCD, secondary LCD or TV output.
  [31:24] VID3GLOBALALPHA — Global alpha value from 0 to 255. 0 corresponds to fully transparent and 255 to fully opaque.
  [23:16] VID2GLOBALALPHA — Global alpha value from 0 to 255. 0 corresponds to fully transparent and 255 to fully opaque.
  [15:8] VID1GLOBALALPHA — Global alpha value from 0 to 255. 0 corresponds to fully transparent and 255 to fully opaque.
  [7:0] GFXGLOBALALPHA — Global alpha value from 0 to 255. 0 corresponds to fully transparent and 255 to fully opaque.
